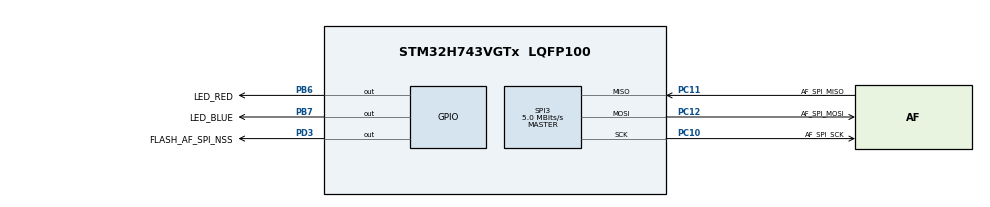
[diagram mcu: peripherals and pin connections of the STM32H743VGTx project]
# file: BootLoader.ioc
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CRC.InputDataFormat=CRC_INPUTDATA_FORMAT_WORDS
Mcu.Family=STM32H7
Mcu.Name=STM32H743VGTx
Mcu.Package=LQFP100
NVIC.PriorityGroup=NVIC_PRIORITYGROUP_4
PA13\ (JTMS/SWDIO).GPIO_Label=SWDIO
PA13\ (JTMS/SWDIO).Mode=Serial_Wire
PA13\ (JTMS/SWDIO).Signal=DEBUG_JTMS-SWDIO
PA14\ (JTCK/SWCLK).GPIO_Label=SWCLK
PA14\ (JTCK/SWCLK).Mode=Serial_Wire
PA14\ (JTCK/SWCLK).Signal=DEBUG_JTCK-SWCLK
PB6.GPIO_Label=LED_RED
PB6.Signal=GPIO_Output
PB7.GPIO_Label=LED_BLUE
PB7.Signal=GPIO_Output
PC10.GPIO_Label=AF_SPI_SCK
PC10.GPIO_Speed=GPIO_SPEED_FREQ_VERY_HIGH
PC10.Mode=Full_Duplex_Master
PC10.Signal=SPI3_SCK
PC11.GPIO_Label=AF_SPI_MISO
PC11.GPIO_Speed=GPIO_SPEED_FREQ_VERY_HIGH
PC11.Mode=Full_Duplex_Master
PC11.Signal=SPI3_MISO
PC12.GPIO_Label=AF_SPI_MOSI
PC12.GPIO_Speed=GPIO_SPEED_FREQ_VERY_HIGH
PC12.Mode=Full_Duplex_Master
PC12.Signal=SPI3_MOSI
PD3.GPIO_Label=FLASH_AF_SPI_NSS
PD3.GPIO_PuPd=GPIO_PULLUP
PD3.GPIO_Speed=GPIO_SPEED_FREQ_VERY_HIGH
PD3.PinState=GPIO_PIN_SET
PD3.Signal=GPIO_Output
PH0-OSC_IN\ (PH0).Mode=HSE-External-Clock-Source
PH0-OSC_IN\ (PH0).Signal=RCC_OSC_IN
ProjectManager.HeapSize=0x200
ProjectManager.StackSize=0x400
ProjectManager.TargetToolchain=MDK-ARM V5.32
RCC.ADCFreq_Value=80000000
RCC.APB1Freq_Value=120000000
RCC.APB2Freq_Value=120000000
RCC.APB3Freq_Value=120000000
RCC.APB4Freq_Value=120000000
RCC.CortexFreq_Value=480000000
RCC.D1PPRE=RCC_APB3_DIV2
RCC.D2PPRE1=RCC_APB1_DIV2
RCC.D2PPRE2=RCC_APB2_DIV2
RCC.D3PPRE=RCC_APB4_DIV2
RCC.DIVM1=1
RCC.DIVM2=1
RCC.DIVN1=60
RCC.DIVN2=10
RCC.DIVQ1=6
RCC.HCLKFreq_Value=240000000
RCC.HPRE=RCC_HCLK_DIV2
RCC.HSE_VALUE=16000000
RCC.PLLFRACN=0
RCC.PLLSourceVirtual=RCC_PLLSOURCE_HSE
RCC.SYSCLKFreq_VALUE=480000000
RCC.SYSCLKSource=RCC_SYSCLKSOURCE_PLLCLK
RCC.USBFreq_Value=160000000
SPI3.BaudRatePrescaler=SPI_BAUDRATEPRESCALER_32
SPI3.CalculateBaudRate=5.0 MBits/s
SPI3.DataSize=SPI_DATASIZE_8BIT
SPI3.Direction=SPI_DIRECTION_2LINES
SPI3.Mode=SPI_MODE_MASTER
SPI3.NSSPMode=SPI_NSS_PULSE_DISABLE
SPI3.VirtualType=VM_MASTER
VP_CRC_VS_CRC.Mode=CRC_Activate
VP_MEMORYMAP_VS_MEMORYMAP.Mode=CurAppReg
board=custom

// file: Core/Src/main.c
/* USER CODE BEGIN Header */
/**
  ******************************************************************************
  * @file           : main.c
  * @brief          : Main program body
  ******************************************************************************
  * @attention
  *
  * Copyright (c) 2026 STMicroelectronics.
  * All rights reserved.
  *
  * This software is licensed under terms that can be found in the LICENSE file
  * in the root directory of this software component.
  * If no LICENSE file comes with this software, it is provided AS-IS.
  *
  ******************************************************************************
  */
/* USER CODE END Header */
#include "main.h"

/* USER CODE BEGIN Includes */
#include "app_boot.h"
/* USER CODE END Includes */

CRC_HandleTypeDef hcrc;

SPI_HandleTypeDef hspi3;

void SystemClock_Config(void);
static void MX_GPIO_Init(void);
static void MX_SPI3_Init(void);
static void MX_CRC_Init(void);

int main(void)
{

  /* MCU Configuration--------------------------------------------------------*/

  /* Reset of all peripherals, Initializes the Flash interface and the Systick. */
  HAL_Init();

  /* Configure the system clock */
  SystemClock_Config();

  /* Initialize all configured peripherals */
  MX_GPIO_Init();
  MX_SPI3_Init();
  MX_CRC_Init();

  /* Infinite loop */
  /* USER CODE BEGIN WHILE */
  while (1)
  {
    boot_run();
    /* USER CODE END WHILE */

  }
}

void SystemClock_Config(void)
{
  RCC_OscInitTypeDef RCC_OscInitStruct = {0};
  RCC_ClkInitTypeDef RCC_ClkInitStruct = {0};

  /** Supply configuration update enable
  */
  HAL_PWREx_ConfigSupply(PWR_LDO_SUPPLY);

  /** Configure the main internal regulator output voltage
  */
  __HAL_PWR_VOLTAGESCALING_CONFIG(PWR_REGULATOR_VOLTAGE_SCALE0);

  while(!__HAL_PWR_GET_FLAG(PWR_FLAG_VOSRDY)) {}

  /** Initializes the RCC Oscillators according to the specified parameters
  * in the RCC_OscInitTypeDef structure.
  */
  RCC_OscInitStruct.OscillatorType = RCC_OSCILLATORTYPE_HSE;
  RCC_OscInitStruct.HSEState = RCC_HSE_BYPASS;
  RCC_OscInitStruct.PLL.PLLState = RCC_PLL_ON;
  RCC_OscInitStruct.PLL.PLLSource = RCC_PLLSOURCE_HSE;
  RCC_OscInitStruct.PLL.PLLM = 1;
  RCC_OscInitStruct.PLL.PLLN = 60;
  RCC_OscInitStruct.PLL.PLLP = 2;
  RCC_OscInitStruct.PLL.PLLQ = 6;
  RCC_OscInitStruct.PLL.PLLR = 2;
  RCC_OscInitStruct.PLL.PLLRGE = RCC_PLL1VCIRANGE_3;
  RCC_OscInitStruct.PLL.PLLVCOSEL = RCC_PLL1VCOWIDE;
  RCC_OscInitStruct.PLL.PLLFRACN = 0;
  if (HAL_RCC_OscConfig(&RCC_OscInitStruct) != HAL_OK)
  {
    Error_Handler();
  }

  /** Initializes the CPU, AHB and APB buses clocks
  */
  RCC_ClkInitStruct.ClockType = RCC_CLOCKTYPE_HCLK|RCC_CLOCKTYPE_SYSCLK
                              |RCC_CLOCKTYPE_PCLK1|RCC_CLOCKTYPE_PCLK2
                              |RCC_CLOCKTYPE_D3PCLK1|RCC_CLOCKTYPE_D1PCLK1;
  RCC_ClkInitStruct.SYSCLKSource = RCC_SYSCLKSOURCE_PLLCLK;
  RCC_ClkInitStruct.SYSCLKDivider = RCC_SYSCLK_DIV1;
  RCC_ClkInitStruct.AHBCLKDivider = RCC_HCLK_DIV2;
  RCC_ClkInitStruct.APB3CLKDivider = RCC_APB3_DIV2;
  RCC_ClkInitStruct.APB1CLKDivider = RCC_APB1_DIV2;
  RCC_ClkInitStruct.APB2CLKDivider = RCC_APB2_DIV2;
  RCC_ClkInitStruct.APB4CLKDivider = RCC_APB4_DIV2;

  if (HAL_RCC_ClockConfig(&RCC_ClkInitStruct, FLASH_LATENCY_4) != HAL_OK)
  {
    Error_Handler();
  }
}

static void MX_CRC_Init(void)
{

  hcrc.Instance = CRC;
  hcrc.Init.DefaultPolynomialUse = DEFAULT_POLYNOMIAL_ENABLE;
  hcrc.Init.DefaultInitValueUse = DEFAULT_INIT_VALUE_ENABLE;
  hcrc.Init.InputDataInversionMode = CRC_INPUTDATA_INVERSION_NONE;
  hcrc.Init.OutputDataInversionMode = CRC_OUTPUTDATA_INVERSION_DISABLE;
  hcrc.InputDataFormat = CRC_INPUTDATA_FORMAT_WORDS;
  if (HAL_CRC_Init(&hcrc) != HAL_OK)
  {
    Error_Handler();
  }

}

static void MX_SPI3_Init(void)
{

  /* SPI3 parameter configuration*/
  hspi3.Instance = SPI3;
  hspi3.Init.Mode = SPI_MODE_MASTER;
  hspi3.Init.Direction = SPI_DIRECTION_2LINES;
  hspi3.Init.DataSize = SPI_DATASIZE_8BIT;
  hspi3.Init.CLKPolarity = SPI_POLARITY_LOW;
  hspi3.Init.CLKPhase = SPI_PHASE_1EDGE;
  hspi3.Init.NSS = SPI_NSS_SOFT;
  hspi3.Init.BaudRatePrescaler = SPI_BAUDRATEPRESCALER_32;
  hspi3.Init.FirstBit = SPI_FIRSTBIT_MSB;
  hspi3.Init.TIMode = SPI_TIMODE_DISABLE;
  hspi3.Init.CRCCalculation = SPI_CRCCALCULATION_DISABLE;
  hspi3.Init.CRCPolynomial = 0x0;
  hspi3.Init.NSSPMode = SPI_NSS_PULSE_DISABLE;
  hspi3.Init.NSSPolarity = SPI_NSS_POLARITY_LOW;
  hspi3.Init.FifoThreshold = SPI_FIFO_THRESHOLD_01DATA;
  hspi3.Init.TxCRCInitializationPattern = SPI_CRC_INITIALIZATION_ALL_ZERO_PATTERN;
  hspi3.Init.RxCRCInitializationPattern = SPI_CRC_INITIALIZATION_ALL_ZERO_PATTERN;
  hspi3.Init.MasterSSIdleness = SPI_MASTER_SS_IDLENESS_00CYCLE;
  hspi3.Init.MasterInterDataIdleness = SPI_MASTER_INTERDATA_IDLENESS_00CYCLE;
  hspi3.Init.MasterReceiverAutoSusp = SPI_MASTER_RX_AUTOSUSP_DISABLE;
  hspi3.Init.MasterKeepIOState = SPI_MASTER_KEEP_IO_STATE_DISABLE;
  hspi3.Init.IOSwap = SPI_IO_SWAP_DISABLE;
  if (HAL_SPI_Init(&hspi3) != HAL_OK)
  {
    Error_Handler();
  }

}

static void MX_GPIO_Init(void)
{
  GPIO_InitTypeDef GPIO_InitStruct = {0};

  /* GPIO Ports Clock Enable */
  __HAL_RCC_GPIOH_CLK_ENABLE();
  __HAL_RCC_GPIOA_CLK_ENABLE();
  __HAL_RCC_GPIOC_CLK_ENABLE();
  __HAL_RCC_GPIOD_CLK_ENABLE();
  __HAL_RCC_GPIOB_CLK_ENABLE();

  /*Configure GPIO pin Output Level */
  HAL_GPIO_WritePin(FLASH_AF_SPI_NSS_GPIO_Port, FLASH_AF_SPI_NSS_Pin, GPIO_PIN_SET);

  /*Configure GPIO pin Output Level */
  HAL_GPIO_WritePin(GPIOB, LED_RED_Pin|LED_BLUE_Pin, GPIO_PIN_RESET);

  /*Configure GPIO pin : FLASH_AF_SPI_NSS_Pin */
  GPIO_InitStruct.Pin = FLASH_AF_SPI_NSS_Pin;
  GPIO_InitStruct.Mode = GPIO_MODE_OUTPUT_PP;
  GPIO_InitStruct.Pull = GPIO_PULLUP;
  GPIO_InitStruct.Speed = GPIO_SPEED_FREQ_VERY_HIGH;
  HAL_GPIO_Init(FLASH_AF_SPI_NSS_GPIO_Port, &GPIO_InitStruct);

  /*Configure GPIO pins : LED_RED_Pin LED_BLUE_Pin */
  GPIO_InitStruct.Pin = LED_RED_Pin|LED_BLUE_Pin;
  GPIO_InitStruct.Mode = GPIO_MODE_OUTPUT_PP;
  GPIO_InitStruct.Pull = GPIO_NOPULL;
  GPIO_InitStruct.Speed = GPIO_SPEED_FREQ_LOW;
  HAL_GPIO_Init(GPIOB, &GPIO_InitStruct);

}

void Error_Handler(void)
{
  __disable_irq();
  while (1)
  {
  }
}
